VERSION ""

NS_ :

BS_:
BU_: STM32F411
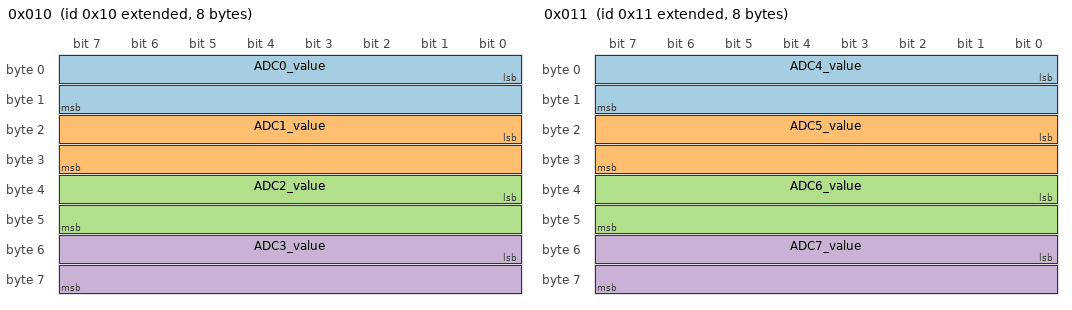
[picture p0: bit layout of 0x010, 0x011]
BO_ 2147483664 0x010: 8 STM32F411
   SG_ ADC0_value : 0|16@1+ (1,0) [0|1] "" Vector__XXX
   SG_ ADC1_value : 16|16@1+ (1,0) [0|1] "" Vector__XXX
   SG_ ADC2_value : 32|16@1+ (1,0) [0|1] "" Vector__XXX
   SG_ ADC3_value : 48|16@1+ (1,0) [0|1] "" Vector__XXX

BO_ 2147483665 0x011: 8 STM32F411
   SG_ ADC4_value : 0|16@1+ (1,0) [0|1] "" Vector__XXX
   SG_ ADC5_value : 16|16@1+ (1,0) [0|1] "" Vector__XXX
   SG_ ADC6_value : 32|16@1+ (1,0) [0|1] "" Vector__XXX
   SG_ ADC7_value : 48|16@1+ (1,0) [0|1] "" Vector__XXX

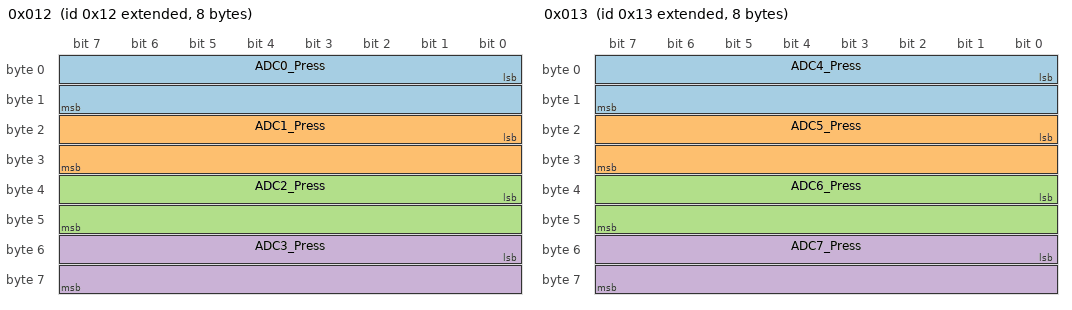
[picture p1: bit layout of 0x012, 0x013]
BO_ 2147483666 0x012: 8 STM32F411
   SG_ ADC0_Press : 0|16@1+ (1,0) [0|1] "" Vector__XXX
   SG_ ADC1_Press : 16|16@1+ (1,0) [0|1] "" Vector__XXX
   SG_ ADC2_Press : 32|16@1+ (1,0) [0|1] "" Vector__XXX
   SG_ ADC3_Press : 48|16@1+ (1,0) [0|1] "" Vector__XXX

BO_ 2147483667 0x013: 8 STM32F411
   SG_ ADC4_Press : 0|16@1+ (1,0) [0|1] "" Vector__XXX
   SG_ ADC5_Press : 16|16@1+ (1,0) [0|1] "" Vector__XXX
   SG_ ADC6_Press : 32|16@1+ (1,0) [0|1] "" Vector__XXX
   SG_ ADC7_Press : 48|16@1+ (1,0) [0|1] "" Vector__XXX

BA_DEF_ BO_ "GenMsgBackgroundColor" STRING ;
BA_DEF_ BO_ "GenMsgForegroundColor" STRING ;
BA_DEF_ BO_ "filterlabeling" INT 0 0;
BA_DEF_DEF_ "GenMsgBackgroundColor" "#ffffff";
BA_DEF_DEF_ "GenMsgForegroundColor" "#000000";
BA_DEF_DEF_ "filterlabeling" 1;
BA_ "GenMsgForegroundColor" BO_ 2147483665 "#e01b24";
BA_ "GenMsgForegroundColor" BO_ 2147483666 "#26a269";
BA_ "GenMsgForegroundColor" BO_ 2147483667 "#1a5fb4";
